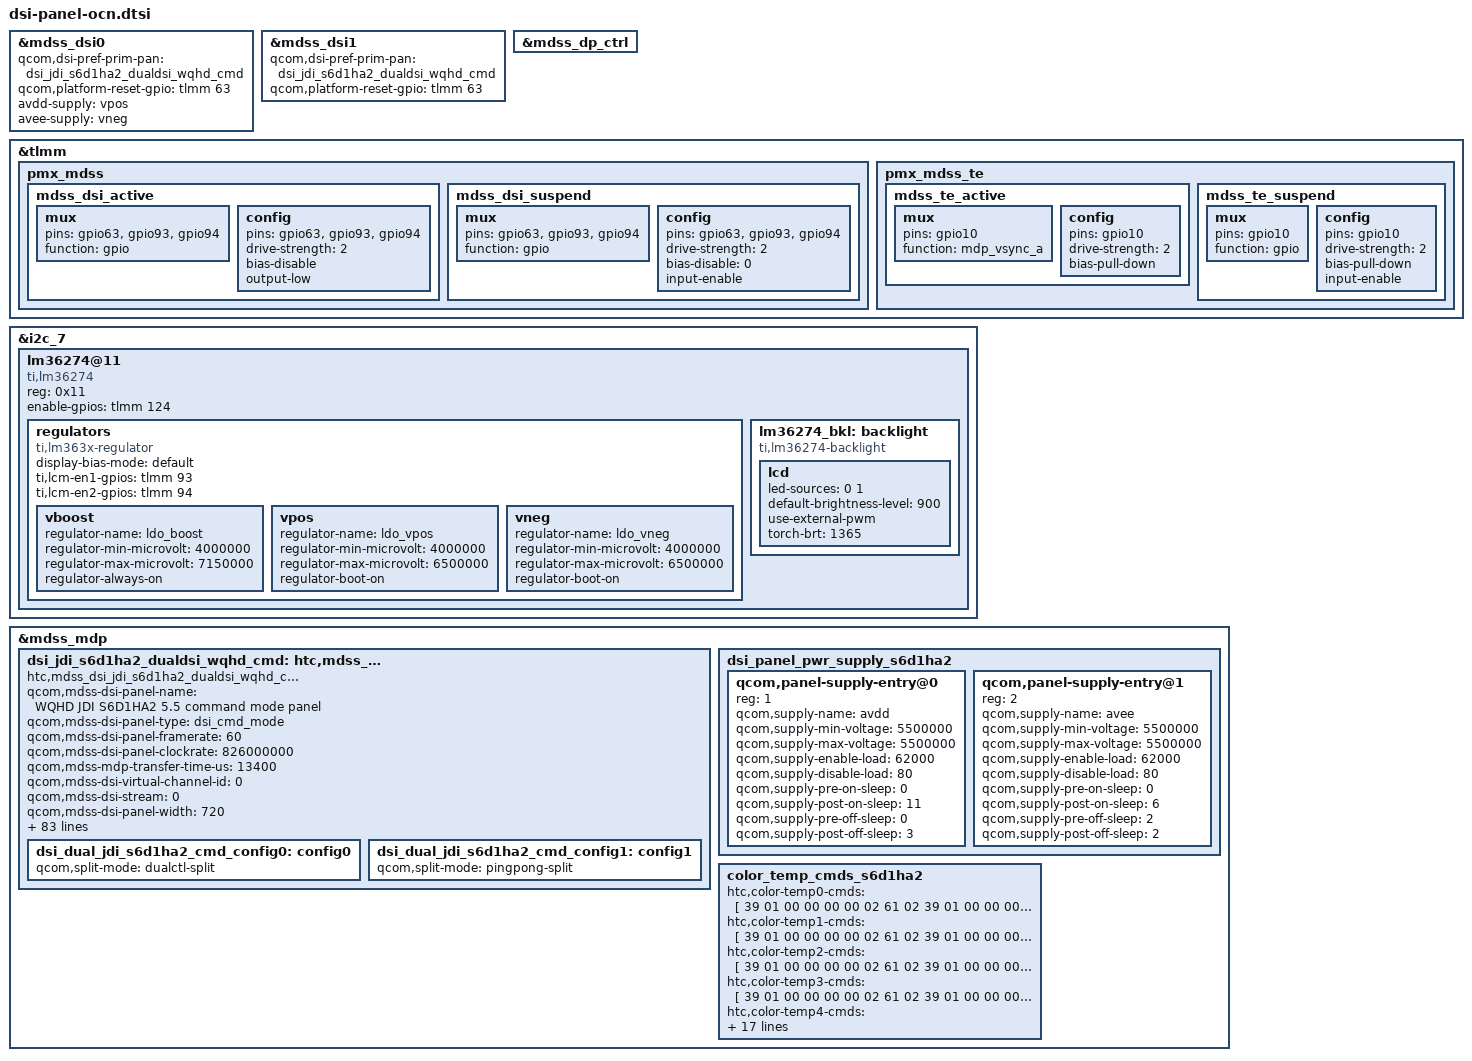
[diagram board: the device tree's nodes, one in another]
/* Copyright (c) 2016, The Linux Foundation. All rights reserved.
 *
 * This program is free software; you can redistribute it and/or modify
 * it under the terms of the GNU General Public License version 2 and
 * only version 2 as published by the Free Software Foundation.
 *
 * This program is distributed in the hope that it will be useful,
 * but WITHOUT ANY WARRANTY; without even the implied warranty of
 * MERCHANTABILITY or FITNESS FOR A PARTICULAR PURPOSE.  See the
 * GNU General Public License for more details.
 */
&mdss_dsi0 {
	qcom,dsi-pref-prim-pan = <&dsi_jdi_s6d1ha2_dualdsi_wqhd_cmd>;
	qcom,platform-reset-gpio = <&tlmm 63 0>;
	/delete-property/qcom,panel-mode-gpio;
	avdd-supply = <&vpos>;
	avee-supply = <&vneg>;
};

&mdss_dsi1 {
	qcom,dsi-pref-prim-pan = <&dsi_jdi_s6d1ha2_dualdsi_wqhd_cmd>;
	qcom,platform-reset-gpio = <&tlmm 63 0>;
	/delete-property/qcom,panel-mode-gpio;
};

&mdss_dp_ctrl {
	/delete-property/pinctrl-0;
	/delete-property/pinctrl-1;
	/delete-property/qcom,aux-en-gpio;
	/delete-property/qcom,aux-sel-gpio;
};

&tlmm {
	pmx_mdss: pmx_mdss {
		mdss_dsi_active: mdss_dsi_active {
			mux {
				pins = "gpio63","gpio93","gpio94";
				function = "gpio";
			};

				config {
				pins = "gpio63","gpio93","gpio94";
				drive-strength = <2>; /* 2 mA */
				/delete-property/bias-pull-down;
				bias-disable;
				output-low;
			};
		};
		mdss_dsi_suspend: mdss_dsi_suspend {
			mux {
				pins = "gpio63","gpio93","gpio94";
				function = "gpio";
			};

				config {
				pins = "gpio63","gpio93","gpio94";
				drive-strength = <2>; /* 2 mA */
				/delete-property/bias-pull-down;
				bias-disable = <0>;
				input-enable;
			};
		};
	};

	pmx_mdss_te {
		mdss_te_active: mdss_te_active {
			mux {
				pins = "gpio10";
				function = "mdp_vsync_a";
			};
			config {
				pins = "gpio10";
				drive-strength = <2>; /* 2 mA */
				bias-pull-down; /* pull down*/
			};
		};
		mdss_te_suspend: mdss_te_suspend {
			mux {
				pins = "gpio10";
				function = "gpio";
			};
			config {
				pins = "gpio10";
				drive-strength = <2>; /* 2 mA */
				bias-pull-down; /* pull down */
				input-enable;
			};
		};
	};
};

&i2c_7 {
	lm36274@11 {
		compatible = "ti,lm36274";
		reg = <0x11>;
		status = "okay";

		enable-gpios = <&tlmm 124 0>; /* BL_HW ENABLE */

		regulators {
			compatible = "ti,lm363x-regulator";
			display-bias-mode = "default";

			ti,lcm-en1-gpios = <&tlmm 93 0>; /* LCM_P5V_EN */
			ti,lcm-en2-gpios = <&tlmm 94 0>; /* LCM_N5V_EN */

			vboost {
				regulator-name = "ldo_boost";
				regulator-min-microvolt = <4000000>;
				regulator-max-microvolt = <7150000>;
				regulator-always-on;
			};

			vpos: vpos {
				regulator-name = "ldo_vpos";
				regulator-min-microvolt = <4000000>;
				regulator-max-microvolt = <6500000>;
				regulator-boot-on;
			};

			vneg: vneg {
				regulator-name = "ldo_vneg";
				regulator-min-microvolt = <4000000>;
				regulator-max-microvolt = <6500000>;
				regulator-boot-on;
			};
		};

		lm36274_bkl: backlight {
			compatible = "ti,lm36274-backlight";

			lcd {
				led-sources = <0 1>;
				default-brightness-level = <900>;
				use-external-pwm;
				torch-brt = <1365>;
			};
		};
	};
};
&mdss_mdp {
	dsi_jdi_s6d1ha2_dualdsi_wqhd_cmd: htc,mdss_dsi_jdi_s6d1ha2_dualdsi_wqhd_cmd {
		compatible = "htc,mdss_dsi_jdi_s6d1ha2_dualdsi_wqhd_cmd";
		qcom,mdss-dsi-panel-name = "WQHD JDI S6D1HA2 5.5 command mode panel";
		qcom,mdss-dsi-panel-type = "dsi_cmd_mode";
		qcom,mdss-dsi-panel-framerate = <60>;
		qcom,mdss-dsi-panel-clockrate = <826000000>;
		qcom,mdss-mdp-transfer-time-us = <13400>;
		qcom,mdss-dsi-virtual-channel-id = <0>;
		qcom,mdss-dsi-stream = <0>;
		qcom,mdss-dsi-panel-width = <720>;
		qcom,mdss-dsi-panel-height = <2560>;
		qcom,mdss-dsi-h-front-porch = <16>;
		qcom,mdss-dsi-h-back-porch = <16>;
		qcom,mdss-dsi-h-pulse-width = <2>;
		qcom,mdss-dsi-h-sync-skew = <0>;
		qcom,mdss-dsi-v-back-porch = <6>;
		qcom,mdss-dsi-v-front-porch = <8>;
		qcom,mdss-dsi-v-pulse-width = <2>;
		qcom,mdss-dsi-h-left-border = <0>;
		qcom,mdss-dsi-h-right-border = <0>;
		qcom,mdss-dsi-v-top-border = <0>;
		qcom,mdss-dsi-v-bottom-border = <0>;
		qcom,mdss-pan-physical-width-dimension  = <68>;
		qcom,mdss-pan-physical-height-dimension = <122>;
		qcom,mdss-dsi-bpp = <24>;
		qcom,mdss-dsi-color-order = "rgb_swap_rgb";
		qcom,mdss-dsi-underflow-color = <0xff>;
		qcom,mdss-dsi-border-color = <0>;
		qcom,mdss-dsi-h-sync-pulse = <0>;
		qcom,mdss-dsi-traffic-mode = "non_burst_sync_event";
		qcom,mdss-dsi-lane-map = "lane_map_0123";
		qcom,mdss-dsi-bllp-eof-power-mode;
		qcom,mdss-dsi-bllp-power-mode;
		qcom,mdss-dsi-panel-broadcast-mode;
		qcom,mdss-dsi-lane-0-state;
		qcom,mdss-dsi-lane-1-state;
		qcom,mdss-dsi-lane-2-state;
		qcom,mdss-dsi-lane-3-state;
		qcom,mdss-dsi-panel-timings = [00 1B 05 06 0A 0E 07 06 05 03 04 00];
		qcom,mdss-dsi-reset-sequence =  <1 20>;
		qcom,mdss-dsi-t-clk-post = <0x07>;
		qcom,mdss-dsi-t-clk-pre = <0x28>;
		qcom,mdss-dsi-bl-pmic-control-type = "bl_ctrl_backlight";
		htc,mdss-dsi-bl-backlight = <&lm36274_bkl>;
		htc,brt-bl-table = <30 15>, <142 364>, <255 1365>;
		htc,mdss-camera-blk = <176>;
		htc,burst-on-level = <13>;
		htc,burst-off-level = <12>;
		htc,burst-bl-value = <1638>;
		htc,color-temp-cmds = <&color_temp_cmds_s6d1ha2>;
		htc,color-rgb-loca = <6>;
		htc,color-rgbcmy-loca = <4>;
		htc,disp-cali-cmds = [
			39 01 00 00 00 00 02 61 02
			39 01 00 00 00 00 03 F0 5A 5A /* unlock */
			39 01 00 00 00 00 03 FC 5A 5A /* unlock */
			39 01 00 00 00 00 03 C0 08 00
			39 01 00 00 00 00 13 C3 FF 00 00 00 FF 00 00 00 FF 00 FF FF FF 00 FF FF FF 00 /* RGBCMY value */
			39 01 00 00 00 00 02 B0 50
			39 01 00 00 00 00 04 C3 FF FF FF /* RGB value */
			39 01 00 00 00 00 03 F0 A5 A5 /* lock */
			39 01 00 00 00 00 03 FC A5 A5 /* lock */
		];
		qcom,mdss-dsi-bl-min-level = <1>;
		qcom,mdss-dsi-bl-max-level = <2047>;
		qcom,mdss-dsi-dma-trigger = "trigger_sw";
		qcom,mdss-dsi-mdp-trigger = "none";
		qcom,mdss-dsi-wr-mem-start = <0x2c>;
		qcom,mdss-dsi-wr-mem-continue = <0x3c>;
		qcom,mdss-dsi-te-pin-select = <1>;
		qcom,mdss-dsi-te-dcs-command = <1>;
		qcom,mdss-dsi-te-check-enable;
		qcom,mdss-dsi-te-using-te-pin;
		qcom,mdss-tear-check-sync-cfg-height = <0x3ff0>;
		qcom,esd-check-enabled;
		qcom,mdss-dsi-panel-status-check-mode = "te_signal_check_v2";
		/* XXX: Don't care */
		qcom,mdss-dsi-panel-status-command = [06 01 00 01 05 00 02 0A 00];
		qcom,mdss-dsi-panel-status-command-state = "dsi_hs_mode";
		qcom,mdss-dsi-panel-status-read-length = <4>;
		qcom,mdss-dsi-panel-max-error-count = <3>;
		qcom,mdss-dsi-panel-status-value = <0x1e 0x1e 0x1e 0x1e>;
		qcom,dcs-cmd-by-left;
		qcom,mdss-dsi-on-command = [
05 01 00 00 0A 00 02 01 00 /* soft reset */
15 01 00 00 00 00 02 35 00 /* TE on */
39 01 00 00 00 00 03 51 03 FF /* brightness value */
15 01 00 00 00 00 02 53 2C /* brightness control */
39 01 00 00 00 00 03 F0 5A 5A /* unlock */
39 01 00 00 00 00 03 FC 5A 5A /* unlock */
39 01 00 00 00 00 03 f1 5a 5a
39 01 00 00 00 00 04 d0 00 00 02 /*SW workaround – Step 1 , Select Bank0 */
39 01 00 00 00 00 0b ff 00 00 02 00 00 00 00 00 00 80 /*SW workaround – Step 1 , Select Bank0 */
15 01 00 00 00 00 02 55 02 /* CABC still mode */
05 01 00 00 0A 00 02 11 00 /* sleep out */
39 01 00 00 00 00 0b ff 80 00 02 00 00 00 00 00 00 00
39 01 00 00 00 00 0b ff 00 00 02 00 00 00 00 00 00 00
39 01 00 00 00 00 02 b0 18
39 01 00 00 00 00 03 f4 9a 1a /*Bias current increase (VGHO, VGLO, GVDD)*/
39 01 00 00 00 00 02 b0 1e
39 01 00 00 00 00 03 f4 04 09 /*Bias current increase (TPL)*/
39 01 00 00 00 00 02 b0 02
39 01 00 00 00 00 02 f2 7b /*SR_SET 5→11 + GSR_SET 4→7*/
39 01 00 00 6E 00 03 f1 a5 a5
39 01 00 00 00 00 3A C4 01 00 20 41 93 5E 72 40 0F FF 06 5B E0 11 41 00 06 5B E0 B0 40 E5 B3 66 25 63 7D 8A 93 A0 AC B2 B9 C1 C8 D6 E2 EA FF FF FF 88 96 A5 B4 BE C8 CD D0 D3 D7 DF E9 ED F3 F8 FF /* CABC setting */
39 01 00 00 00 00 03 F0 A5 A5 /* lock */
39 01 00 00 00 00 03 FC A5 A5 /* lock */
05 01 00 00 00 00 02 29 00 /* display on */
	];
		qcom,mdss-dsi-on-command-state = "dsi_lp_mode";
		qcom,mdss-dsi-off-command = [
			05 01 00 00 23 00 02 28 00
			05 01 00 00 78 00 02 10 00
		];
		qcom,mdss-dsi-off-command-state = "dsi_hs_mode";
		qcom,mdss-dsi-default-command-state = "dsi_hs_mode";
		/*qcom,cont-splash-enabled;*/
		qcom,mdss-dsi-lp11-init;
		qcom,panel-supply-entries = <&dsi_panel_pwr_supply_s6d1ha2>;
		qcom,config-select = <&dsi_dual_jdi_s6d1ha2_cmd_config1>;

		dsi_dual_jdi_s6d1ha2_cmd_config0: config0 {
			qcom,split-mode = "dualctl-split";
		};

		dsi_dual_jdi_s6d1ha2_cmd_config1: config1 {
			qcom,split-mode = "pingpong-split";
		};
		/*qcom,mdss-dsi-panel-status-check-mode = "te_signal_check";*/
	};
	dsi_panel_pwr_supply_s6d1ha2: dsi_panel_pwr_supply_s6d1ha2 {
		#address-cells = <1>;
		#size-cells = <0>;
		qcom,panel-supply-entry@0 {
			reg = <1>;
			qcom,supply-name = "avdd";
			qcom,supply-min-voltage = <5500000>;
			qcom,supply-max-voltage = <5500000>;
			qcom,supply-enable-load = <62000>;
			qcom,supply-disable-load = <80>;
			qcom,supply-pre-on-sleep = <0>;
			qcom,supply-post-on-sleep = <11>;
			qcom,supply-pre-off-sleep = <0>;
			qcom,supply-post-off-sleep = <3>;
		};
		qcom,panel-supply-entry@1 {
			reg = <2>;
			qcom,supply-name = "avee";
			qcom,supply-min-voltage = <5500000>;
			qcom,supply-max-voltage = <5500000>;
			qcom,supply-enable-load = <62000>;
			qcom,supply-disable-load = <80>;
			qcom,supply-pre-on-sleep = <0>;
			qcom,supply-post-on-sleep = <6>;
			qcom,supply-pre-off-sleep = <2>;
			qcom,supply-post-off-sleep = <2>;
		};
	};
	color_temp_cmds_s6d1ha2: color_temp_cmds_s6d1ha2 {
		htc,color-temp0-cmds = [
			39 01 00 00 00 00 02 61 02
			39 01 00 00 00 00 03 F0 5A 5A /* unlock */
			39 01 00 00 00 00 03 FC 5A 5A /* unlock */
			39 01 00 00 00 00 03 C0 08 00
			39 01 00 00 00 00 13 C3 FF 00 00 00 AD 00 00 00 66 00 AD 66 FF 00 66 FF AD 00
			39 01 00 00 00 00 02 B0 50
			39 01 00 00 00 00 04 C3 FF AD 66 /* RGB value */
			39 01 00 00 00 00 03 F0 A5 A5 /* lock */
			39 01 00 00 00 00 03 FC A5 A5 /* lock */
		];
		htc,color-temp1-cmds = [
			39 01 00 00 00 00 02 61 02
			39 01 00 00 00 00 03 F0 5A 5A /* unlock */
			39 01 00 00 00 00 03 FC 5A 5A /* unlock */
			39 01 00 00 00 00 03 C0 08 00
			39 01 00 00 00 00 13 C3 FF 00 00 00 C1 00 00 00 83 00 C1 83 FF 00 83 FF C1 00
			39 01 00 00 00 00 02 B0 50
			39 01 00 00 00 00 04 C3 FF C1 83 /* RGB value */
			39 01 00 00 00 00 03 F0 A5 A5 /* lock */
			39 01 00 00 00 00 03 FC A5 A5 /* lock */
		];
		htc,color-temp2-cmds = [
			39 01 00 00 00 00 02 61 02
			39 01 00 00 00 00 03 F0 5A 5A /* unlock */
			39 01 00 00 00 00 03 FC 5A 5A /* unlock */
			39 01 00 00 00 00 03 C0 08 00
			39 01 00 00 00 00 13 C3 FF 00 00 00 CF 00 00 00 9B 00 CF 9B FF 00 9B FF CF 00
			39 01 00 00 00 00 02 B0 50
			39 01 00 00 00 00 04 C3 FF CF 9B /* RGB value */
			39 01 00 00 00 00 03 F0 A5 A5 /* lock */
			39 01 00 00 00 00 03 FC A5 A5 /* lock */
		];
		htc,color-temp3-cmds = [
			39 01 00 00 00 00 02 61 02
			39 01 00 00 00 00 03 F0 5A 5A /* unlock */
			39 01 00 00 00 00 03 FC 5A 5A /* unlock */
			39 01 00 00 00 00 03 C0 08 00
			39 01 00 00 00 00 13 C3 FF 00 00 00 DE 00 00 00 B7 00 DE B7 FF 00 B7 FF DE 00
			39 01 00 00 00 00 02 B0 50
			39 01 00 00 00 00 04 C3 FF DE B7 /* RGB value */
			39 01 00 00 00 00 03 F0 A5 A5 /* lock */
			39 01 00 00 00 00 03 FC A5 A5 /* lock */
		];
		htc,color-temp4-cmds = [
			39 01 00 00 00 00 02 61 02
			39 01 00 00 00 00 03 F0 5A 5A /* unlock */
			39 01 00 00 00 00 03 FC 5A 5A /* unlock */
			39 01 00 00 00 00 03 C0 08 00
			39 01 00 00 00 00 13 C3 FF 00 00 00 FC 00 00 00 DD 00 FC DD FF 00 DD FF FC 00
			39 01 00 00 00 00 02 B0 50
			39 01 00 00 00 00 04 C3 FF FC DD /* RGB value */
			39 01 00 00 00 00 03 F0 A5 A5 /* lock */
			39 01 00 00 00 00 03 FC A5 A5 /* lock */
		];
		htc,color-temp5-cmds = [
			39 01 00 00 00 00 02 61 02
			39 01 00 00 00 00 03 F0 5A 5A /* unlock */
			39 01 00 00 00 00 03 FC 5A 5A /* unlock */
			39 01 00 00 00 00 03 C0 08 00
			39 01 00 00 00 00 13 C3 FF 00 00 00 FD 00 00 00 E6 00 FD E6 FF 00 E6 FF FD 00
			39 01 00 00 00 00 02 B0 50
			39 01 00 00 00 00 04 C3 FF FD E6 /* RGB value */
			39 01 00 00 00 00 03 F0 A5 A5 /* lock */
			39 01 00 00 00 00 03 FC A5 A5 /* lock */
		];
		htc,color-temp6-cmds = [
			39 01 00 00 00 00 02 61 02
			39 01 00 00 00 00 03 F0 5A 5A /* unlock */
			39 01 00 00 00 00 03 FC 5A 5A /* unlock */
			39 01 00 00 00 00 03 C0 08 00
			39 01 00 00 00 00 13 C3 FF 00 00 00 FD 00 00 00 EF 00 FD EF FF 00 EF FF FD 00
			39 01 00 00 00 00 02 B0 50
			39 01 00 00 00 00 04 C3 FF FD EF /* RGB value */
			39 01 00 00 00 00 03 F0 A5 A5 /* lock */
			39 01 00 00 00 00 03 FC A5 A5 /* lock */
		];
		htc,color-temp7-cmds = [
			39 01 00 00 00 00 02 61 02
			39 01 00 00 00 00 03 F0 5A 5A /* unlock */
			39 01 00 00 00 00 03 FC 5A 5A /* unlock */
			39 01 00 00 00 00 03 C0 08 00
			39 01 00 00 00 00 13 C3 FF 00 00 00 FE 00 00 00 F6 00 FE F6 FF 00 F6 FF FE 00
			39 01 00 00 00 00 02 B0 50
			39 01 00 00 00 00 04 C3 FF FE F6 /* RGB value */
			39 01 00 00 00 00 03 F0 A5 A5 /* lock */
			39 01 00 00 00 00 03 FC A5 A5 /* lock */
		];
		htc,color-temp8-cmds = [
			39 01 00 00 00 00 02 61 02
			39 01 00 00 00 00 03 F0 5A 5A /* unlock */
			39 01 00 00 00 00 03 FC 5A 5A /* unlock */
			39 01 00 00 00 00 03 C0 08 00
			39 01 00 00 00 00 13 C3 FF 00 00 00 FF 00 00 00 FF 00 FF FF FF 00 FF FF FF 00
			39 01 00 00 00 00 02 B0 50
			39 01 00 00 00 00 04 C3 FF FF FF /* RGB value */
			39 01 00 00 00 00 03 F0 A5 A5 /* lock */
			39 01 00 00 00 00 03 FC A5 A5 /* lock */
		];
		htc,color-temp9-cmds = [
			39 01 00 00 00 00 02 61 02
			39 01 00 00 00 00 03 F0 5A 5A /* unlock */
			39 01 00 00 00 00 03 FC 5A 5A /* unlock */
			39 01 00 00 00 00 03 C0 08 00
			39 01 00 00 00 00 13 C3 F6 00 00 00 FF 00 00 00 FF 00 FF FF F6 00 FF F6 FF 00
			39 01 00 00 00 00 02 B0 50
			39 01 00 00 00 00 04 C3 F6 FF FF /* RGB value */
			39 01 00 00 00 00 03 F0 A5 A5 /* lock */
			39 01 00 00 00 00 03 FC A5 A5 /* lock */
		];
		htc,color-temp10-cmds = [
			39 01 00 00 00 00 02 61 02
			39 01 00 00 00 00 03 F0 5A 5A /* unlock */
			39 01 00 00 00 00 03 FC 5A 5A /* unlock */
			39 01 00 00 00 00 03 C0 08 00
			39 01 00 00 00 00 13 C3 F1 00 00 00 FE 00 00 00 FF 00 FE FF F1 00 FF F1 FE 00
			39 01 00 00 00 00 02 B0 50
			39 01 00 00 00 00 04 C3 F1 FE FF /* RGB value */
			39 01 00 00 00 00 03 F0 A5 A5 /* lock */
			39 01 00 00 00 00 03 FC A5 A5 /* lock */
		];
		htc,color-temp11-cmds = [
			39 01 00 00 00 00 02 61 02
			39 01 00 00 00 00 03 F0 5A 5A /* unlock */
			39 01 00 00 00 00 03 FC 5A 5A /* unlock */
			39 01 00 00 00 00 03 C0 08 00
			39 01 00 00 00 00 13 C3 ED 00 00 00 FD 00 00 00 FF 00 FD FF ED 00 FF ED FD 00
			39 01 00 00 00 00 02 B0 50
			39 01 00 00 00 00 04 C3 ED FD FF /* RGB value */
			39 01 00 00 00 00 03 F0 A5 A5 /* lock */
			39 01 00 00 00 00 03 FC A5 A5 /* lock */
		];
		htc,color-temp12-cmds = [
			39 01 00 00 00 00 02 61 02
			39 01 00 00 00 00 03 F0 5A 5A /* unlock */
			39 01 00 00 00 00 03 FC 5A 5A /* unlock */
			39 01 00 00 00 00 03 C0 08 00
			39 01 00 00 00 00 13 C3 E8 00 00 00 FB 00 00 00 FF 00 FB FF E8 00 FF E8 FB 00
			39 01 00 00 00 00 02 B0 50
			39 01 00 00 00 00 04 C3 E8 FB FF /* RGB value */
			39 01 00 00 00 00 03 F0 A5 A5 /* lock */
			39 01 00 00 00 00 03 FC A5 A5 /* lock */
		];
	};
};
